# STM32N645 register map
File version: 1.0
CPU: CM55 r0p1, little endian, no MPU, FPU, vendor SysTick, 8 interrupt priority bits
Registers are 32-bit, read-write, reset 0x0 unless marked. A register's access mark holds for its fields unless they carry their own. Offsets are from the block's base; [hi:lo] are bit positions; 'fields as' and 'values as' point back to an identical list.

## XSPI1 — Extended-SPI interface
Base 0x48025000
Same registers: XSPI2 0x4802A000, XSPI3 0x4802D000, XSPI1_S 0x58025000, XSPI2_S 0x5802A000, XSPI3_S 0x5802D000
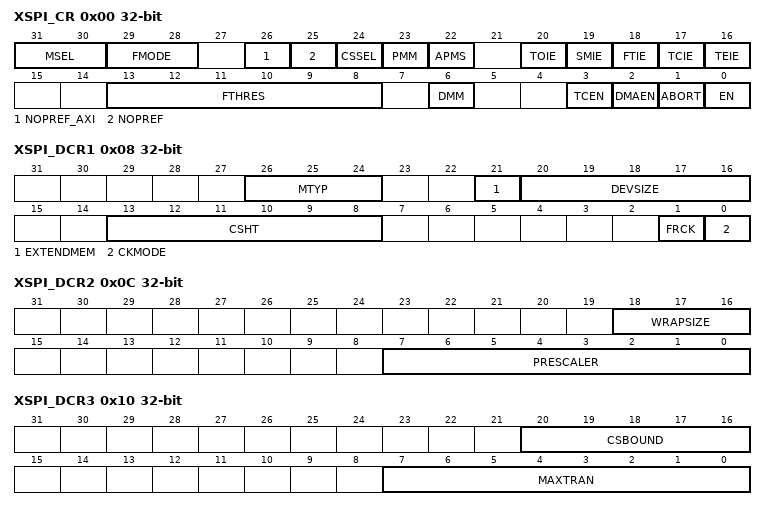
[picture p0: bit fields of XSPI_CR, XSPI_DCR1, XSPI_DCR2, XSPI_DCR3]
0x00 XSPI_CR — XSPI control register
  [31:30] MSEL — Flash select
    0=data exchanged over IO[3:0]; 1=data exchanged over IO[7:4]; 2=data exchanged over IO[11:8]; 3=data exchanged over IO[15:12]
  [29:28] FMODE — Functional mode
    0=indirect-write mode; 1=indirect-read mode; 2=automatic status-polling mode; 3=memory-mapped mode
  [26] NOPREF_AXI — no prefetch for signaled AXI transactions
    0=prefetch is enabled for AXI signaled transactions; 1=prefetch is disable for AXI signaled transactions
  [25] NOPREF — no prefetch data
    0=automatic prefetch enabled; 1=automatic prefetch disabled
  [24] CSSEL — chip select selection
    0=NCS1 active; 1=NCS2 active
  [23] PMM — Polling match mode
    0=AND-match mode, SMF is set if all the unmasked bits received from the device match the corresponding bits in the match register; 1=OR-match mode, SMF is set if any of the unmasked bits received from the device matches its corresponding bit in the match register
  [22] APMS — Automatic status-polling mode stop
    0=Automatic status-polling mode is stopped only by abort or by disabling the XSPI; 1=Automatic status-polling mode stops as soon as there is a match
  [20] TOIE — Timeout interrupt enable
    0=interrupt disabled; 1=interrupt enabled
  [19] SMIE — Status match interrupt enable
    0=interrupt disabled; 1=interrupt enabled
  [18] FTIE — FIFO threshold interrupt enable
    0=interrupt disabled; 1=interrupt enabled
  [17] TCIE — Transfer complete interrupt enable
    0=interrupt disabled; 1=interrupt enabled
  [16] TEIE — Transfer error interrupt enable
    0=interrupt disabled; 1=interrupt enabled
  [13:8] FTHRES — FIFO threshold level
    0=FTF is set if there are one or more free bytes available to be written to in the FIFO in indirect-write mode, or if there are one or more valid bytes can be read from the FIFO in indirect-read mode; 1=FTF is set if there are two or more free bytes available to be written to in the FIFO in indirect-write mode, or if there are two or more valid bytes can be read from the FIFO in indirect-read mode; 63=FTF is set if there are 64 free bytes available to be written to in the FIFO in indirect-write mode, or if there are 64 valid bytes can be read from the FIFO in indirect-read mode
  [6] DMM — Dual-memory configuration
    0=dual-memory configuration disabled; 1=dual-memory configuration enabled
  [3] TCEN — Timeout counter enable
    0=timeout counter is disabled, and thus the chip-select (NCS) remains active indefinitely after an access in memory-mapped mode; 1=timeout counter is enabled, and thus the chip-select is released in the memory-mapped mode after TIMEOUT[15:0] cycles of external device inactivity
  [2] DMAEN — DMA enable
    0=DMA disabled for indirect mode; 1=DMA enabled for indirect mode
  [1] ABORT — Abort request
    0=no abort requested; 1=abort requested
  [0] EN — Enable
    0=XSPI disabled; 1=XSPI enabled
0x08 XSPI_DCR1 access per field — XSPI device configuration register 1
  [26:24] MTYP rw — Memory type
    0=Micron mode, D0/D1 ordering in DTR 8-data-bit mode. Regular-command protocol in single-, dual-, quad-, and octal-SPI modes.; 1=Macronix mode, D1/D0 ordering in DTR 8-data-bit mode. Regular-command protocol in single-, dual-, quad-, and octal-SPI modes.; 2=Standard mode; 3=Macronix RAM mode, D1/D0 ordering in DTR 8-data-bit mode. Regular-command protocol in single-, dual-, quad-, and octal-SPI modes with dedicated address mapping.; 4=HyperBus memory mode, the protocol follows the HyperBus less than sup> less than /sup>specification. 8-data-bit DTR mode must be selected.; 5=HyperBus register mode, addressing register space. The memory-mapped accesses in this mode must be non-cacheable, or indirect read/write modes must be used.
  [21] EXTENDMEM rw — extended memory support
    0=NCS1 and NCS2 values depend from CSSEL bit in XSPI_CR (software controlled); 1=NCS1 and NCS2 values depend from the address of transfer (hardware controlled)
  [20:16] DEVSIZE rw — Device size
  [13:8] CSHT rw — Chip-select high time
    0=NCS stays high for at least 1 cycle between external device commands; 1=NCS stays high for at least 2 cycles between external device commands; 63=NCS stays high for at least 64 cycles between external device commands
  [1] FRCK rw — Free running clock
    0=CLK is not free running; 1=CLK is free running (always provided)
  [0] CKMODE ro — clock mode 0
0x0C XSPI_DCR2 — XSPI device configuration register 2
  [18:16] WRAPSIZE
    0=wrapped reads are not supported by the memory; 2=external memory supports wrap size of 16 bytes; 3=external memory supports wrap size of 32 bytes; 4=external memory supports wrap size of 64 bytes; 5=external memory supports wrap size of 128 bytes
  [7:0] PRESCALER — Clock prescaler
    0=F less than sub>CLK less than /sub> = F less than sub>KERNEL less than /sub>, kernel clock used directly as XSPI CLK (prescaler bypassed). In this case, if the DTR mode is used, it is mandatory to provide to the XSPI a kernel clock that has 50% duty-cycle.; 1=F less than sub>CLK less than /sub> = F less than sub>KERNEL less than /sub>/2
0x10 XSPI_DCR3 — XSPI device configuration register 3
  [20:16] CSBOUND — NCS boundary
    0=NCS boundary disabled
  [7:0] MAXTRAN — Maximum transfer
    0=maximum communication disabled
0x14 XSPI_DCR4 — XSPI device configuration register 4
  [31:0] REFRESH — Refresh rate
    0=refresh disabled
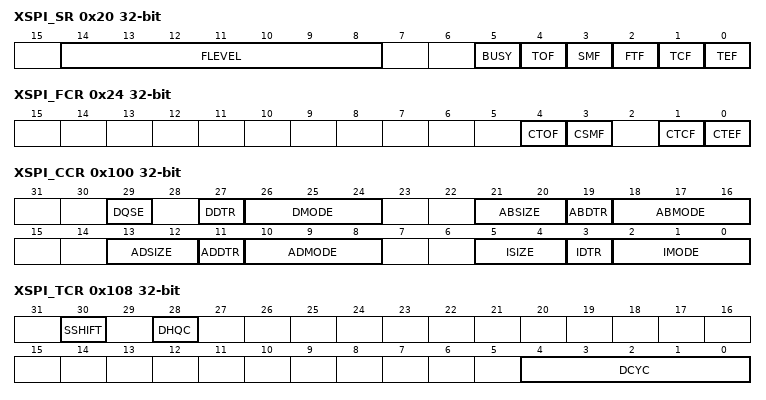
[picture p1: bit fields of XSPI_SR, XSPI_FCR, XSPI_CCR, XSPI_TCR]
0x20 XSPI_SR ro — XSPI status register
  [14:8] FLEVEL — FIFO level
  [5] BUSY
  [4] TOF — Timeout flag
  [3] SMF — Status match flag
  [2] FTF — FIFO threshold flag
  [1] TCF — Transfer complete flag
  [0] TEF — Transfer error flag
0x24 XSPI_FCR wo — XSPI flag clear register
  [4] CTOF — Clear timeout flag
  [3] CSMF — Clear status match flag
  [1] CTCF — Clear transfer complete flag
  [0] CTEF — Clear transfer error flag
0x40 XSPI_DLR — XSPI data length register
  [31:0] DL
0x48 XSPI_AR — XSPIaddress register
  [31:0] ADDRESS
0x50 XSPI_DR — XSPI data register
  [31:0] DATA
0x80 XSPI_PSMKR — XSPI polling status mask register
  [31:0] MASK — Status mask
    0=bit n of the data received in automatic status-polling mode is masked and its value is not considered in the matching logic; 1=bit n of the data received in automatic status-polling mode is unmasked and its value is considered in the matching logic
0x88 XSPI_PSMAR — XSPI polling status match register
  [31:0] MATCH
0x90 XSPI_PIR — XSPI polling interval register
  [15:0] INTERVAL
0x100 XSPI_CCR — XSPI communication configuration register
  [29] DQSE — DQS enable
    0=DQS disabled; 1=DQS enabled
  [27] DDTR — Data double transfer rate
    0=DTR mode disabled for data phase; 1=DTR mode enabled for data phase
  [26:24] DMODE — Data mode
    0=no data; 1=data on a single line; 2=data on two lines; 3=data on four lines; 4=data on eight lines; 5=data on 16 lines
  [21:20] ABSIZE — Alternate bytes size
    0=8-bit alternate bytes; 1=16-bit alternate bytes; 2=24-bit alternate bytes; 3=32-bit alternate bytes
  [19] ABDTR — Alternate bytes double transfer rate
    0=DTR mode disabled for alternate bytes phase; 1=DTR mode enabled for alternate bytes phase
  [18:16] ABMODE — Alternate-byte mode
    0=no alternate bytes; 1=alternate bytes on a single line; 2=alternate bytes on two lines; 3=alternate bytes on four lines
  [13:12] ADSIZE — Address size
    0=8-bit address; 1=16-bit address; 2=24-bit address; 3=32-bit address
  [11] ADDTR — Address double transfer rate
    0=DTR mode disabled for address phase; 1=DTR mode enabled for address phase
  [10:8] ADMODE — Address mode
    0=no address; 1=address on a single line; 2=address on two lines; 3=address on four lines; 4=address on eight lines
  [5:4] ISIZE — Instruction size
    0=8-bit instruction; 1=16-bit instruction; 2=24-bit instruction; 3=32-bit instruction
  [3] IDTR — Instruction double transfer rate
    0=DTR mode disabled for instruction phase; 1=DTR mode enabled for instruction phase
  [2:0] IMODE — Instruction mode
    0=no instruction; 1=instruction on a single line; 2=instruction on two lines; 3=instruction on four lines; 4=instruction on eight lines
0x108 XSPI_TCR — XSPI timing configuration register
  [30] SSHIFT — Sample shift
    0=no shift; 1=1/2 cycle shift
  [28] DHQC — Delay hold quarter cycle
    0=no delay hold; 1=1/4 cycle hold
  [4:0] DCYC — Number of dummy cycles
0x110 XSPI_IR — XSPI instruction register
  [31:0] INSTRUCTION
0x120 XSPI_ABR — XSPI alternate bytes register
  [31:0] ALTERNATE
0x130 XSPI_LPTR — XSPI low-power timeout register
  [15:0] TIMEOUT
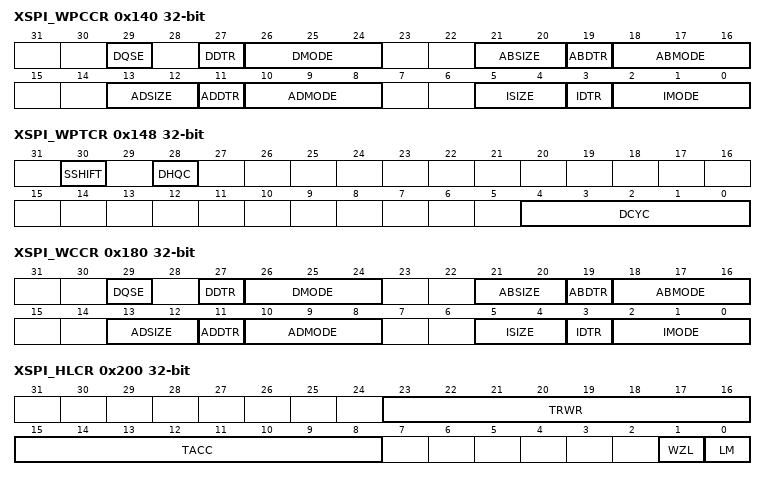
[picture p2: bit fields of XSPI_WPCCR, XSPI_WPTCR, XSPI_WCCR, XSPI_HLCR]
0x140 XSPI_WPCCR — XSPI wrap communication configuration register
  [29] DQSE — DQS enable
    0=DQS disabled; 1=DQS enabled
  [27] DDTR — Data double transfer rate
    values as XSPI_CCR.DDTR
  [26:24] DMODE — Data mode
    0=no data; 1=data on a single line; 2=data on two lines; 3=data on four lines; 4=data on eight lines
  [21:20] ABSIZE — Alternate bytes size
    values as XSPI_CCR.ABSIZE
  [19] ABDTR — Alternate bytes double transfer rate
    values as XSPI_CCR.ABDTR
  [18:16] ABMODE — Alternate-byte mode
    0=no alternate bytes; 1=alternate bytes on a single line; 2=alternate bytes on two lines; 3=alternate bytes on four lines; 4=alternate bytes on eight lines; 5=alternate bytes on 16 lines
  [13:12] ADSIZE — Address size
    values as XSPI_CCR.ADSIZE
  [11] ADDTR — Address double transfer rate
    values as XSPI_CCR.ADDTR
  [10:8] ADMODE — Address mode
    values as XSPI_CCR.ADMODE
  [5:4] ISIZE — Instruction size
    values as XSPI_CCR.ISIZE
  [3] IDTR — Instruction double transfer rate
    values as XSPI_CCR.IDTR
  [2:0] IMODE — Instruction mode
    values as XSPI_CCR.IMODE
0x148 XSPI_WPTCR — XSPI wrap timing configuration register
  [30] SSHIFT — Sample shift
    0=no shift; 1=1/2 cycle shift
  [28] DHQC — Delay hold quarter cycle
    0=no quarter cycle delay; 1=quarter cycle delay inserted
  [4:0] DCYC — Number of dummy cycles
0x150 XSPI_WPIR — XSPI wrap instruction register
  [31:0] INSTRUCTION
0x160 XSPI_WPABR — XSPI wrap alternate byte register
  [31:0] ALTERNATE
0x180 XSPI_WCCR — XSPI write communication configuration register
  [29] DQSE — DQS enable
    0=DQS disabled; 1=DQS enabled
  [27] DDTR — data double transfer rate
    values as XSPI_CCR.DDTR
  [26:24] DMODE — Data mode
    0=no data; 1=data on a single line; 2=data on two lines; 3=data on four lines; 4=data on eight lines; 5=Data on 16 lines
  [21:20] ABSIZE — Alternate bytes size
    values as XSPI_CCR.ABSIZE
  [19] ABDTR — Alternate bytes double-transfer rate
    0=DTR mode disabled for alternate-bytes phase; 1=DTR mode enabled for alternate-bytes phase
  [18:16] ABMODE — Alternate-byte mode
    0=no alternate bytes; 1=alternate bytes on a single line; 2=alternate bytes on two lines; 3=alternate bytes on four lines; 4=alternate bytes on eight lines
  [13:12] ADSIZE — Address size
    values as XSPI_CCR.ADSIZE
  [11] ADDTR — Address double transfer rate
    values as XSPI_CCR.ADDTR
  [10:8] ADMODE — Address mode
    values as XSPI_CCR.ADMODE
  [5:4] ISIZE — Instruction size
    values as XSPI_CCR.ISIZE
  [3] IDTR — Instruction double transfer rate
    values as XSPI_CCR.IDTR
  [2:0] IMODE — Instruction mode
    values as XSPI_CCR.IMODE
0x188 XSPI_WTCR — XSPI write timing configuration register
  [4:0] DCYC — Number of dummy cycles
0x190 XSPI_WIR — XSPI write instruction register
  [31:0] INSTRUCTION
0x1A0 XSPI_WABR — XSPI write alternate byte register
  [31:0] ALTERNATE
0x200 XSPI_HLCR — XSPI HyperBus latency configuration register
  [23:16] TRWR — Read write recovery time
  [15:8] TACC
  [1] WZL — Write zero latency
    0=latency on write accesses; 1=no latency on write accesses
  [0] LM — Latency mode
    0=Variable initial latency; 1=Fixed latency
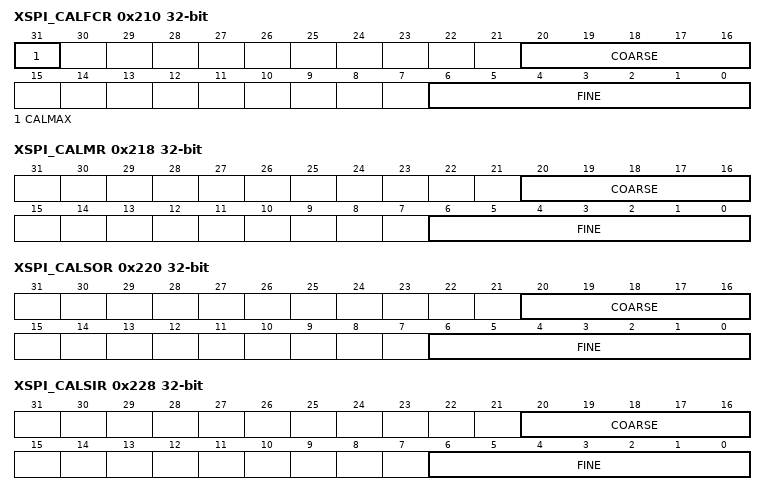
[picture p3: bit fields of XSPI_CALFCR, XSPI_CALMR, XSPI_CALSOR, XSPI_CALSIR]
0x210 XSPI_CALFCR ro — XSPI full-cycle calibration configuration
  [31] CALMAX — Max value
  [20:16] COARSE
  [6:0] FINE
0x218 XSPI_CALMR — XSPI DLL master calibration configuration
  [20:16] COARSE, [6:0] FINE
0x220 XSPI_CALSOR — XSPI DLL slave output calibration configuration
  [20:16] COARSE, [6:0] FINE
0x228 XSPI_CALSIR — XSPI DLL slave input calibration configuration
  [20:16] COARSE, [6:0] FINE
